# PY32F040xx register map
Vendor: Puya; Series: PY32F0; File version: 1.0.0
CPU: CM0+ r0p1, little endian, no MPU, no FPU, 4 interrupt priority bits
Registers are 32-bit, read-write, reset 0x0 unless marked. A register's access mark holds for its fields unless they carry their own. Offsets are from the block's base; [hi:lo] are bit positions; {n}, {i} and the like mark numbered series; 'fields as' and 'values as' point back to an identical list.

## ADC — Analog to Digital Converter
Base 0x40012400
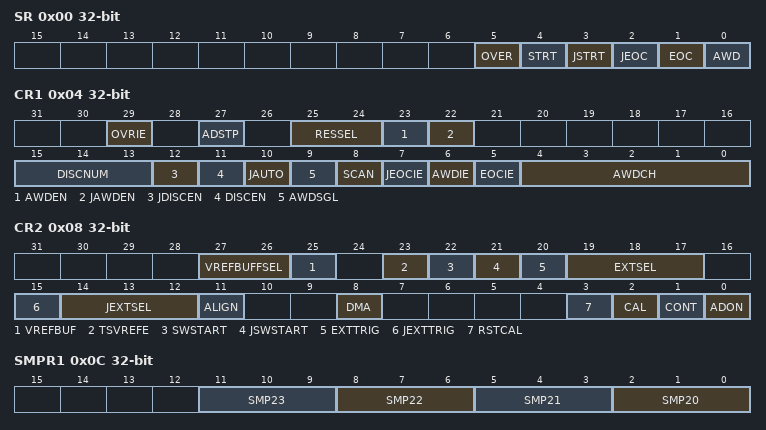
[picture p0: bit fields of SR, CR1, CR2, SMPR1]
0x00 SR
  [5] OVER
    on read: 0=No overload occurred; 1=Overload occurred | on write: 0=Clear the overload flag
  [4] STRT write-0-clears
    on read: 0=NotStarted (Rule channel conversion has not started); 1=Started (Rule channel conversion started) | on write: 0=Clear the Rule channel conversion start flag
  [3] JSTRT write-0-clears
    on read: 0=NotStarted (Injection channel conversion has not started); 1=Started (Injection channel conversion started) | on write: 0=Clear the Injection channel conversion start flag
  [2] JEOC write-0-clears
    on read: 0=NotComplete (Injection channel conversion is not complete); 1=Complete (Injection channel conversion complete) | on write: 0=Clear the Injection channel conversion flag
  [1] EOC write-0-clears
    on read: 0=NotComplete (Channel conversion is not complete); 1=Complete (Channel conversion complete) | on write: 0=Clear the channel conversion flag
  [0] AWD write-0-clears
    on read: 0=NoEvent (No analog watchdog event occurred); 1=Event (Analog watchdog event occurred) | on write: 0=Clear the analog watchdog event flag
0x04 CR1
  [29] OVRIE — desc OVETIE
    0=Disabled (Overload interrupt disabled); 1=Enabled (Overload interrupt enabled)
  [27] ADSTP
    on read: 0=NotStopping (No stop command active); 1=Stopping (ADC stopping conversion) | on write: 1=StopConversion (Stop the active conversion)
  [25:24] RESSEL
    0=TwelveBit (12 bits); 1=TenBit (10 bits); 2=EightBit (8 bits); 3=SixBit (6 bits)
  [23] AWDEN
    0=Disabled (Analog rule channel watchdog disabled); 1=Enabled (Analog rule channel watchdog enabled)
  [22] JAWDEN
    0=Disabled (Analog inject channel watchdog disabled); 1=Enabled (Analog inject channel watchdog enabled)
  [15:13] DISCNUM
  [12] JDISCEN
    0=Disabled (Analog inject channel intermittent mode disabled); 1=Enabled (Analog inject channel intermittent mode enabled)
  [11] DISCEN
    0=Disabled (Analog rule channel intermittent mode disabled); 1=Enabled (Analog rule channel intermittent mode enabled)
  [10] JAUTO
    0=Disabled (Analog auto inject disabled); 1=Enabled (Analog auto inject enabled)
  [9] AWDSGL
    0=Disabled (Analog watchdog on single channel disabled); 1=Enabled (Analog watchdog on single channel enabled)
  [8] SCAN
    0=Off (Scan mode off); 1=On (Scan mode on)
  [7] JEOCIE
    0=Disabled (Injection channel conversion end interrupt disabled); 1=Enabled (Injection channel conversion end interrupt enabled)
  [6] AWDIE
    0=Disabled (Analog watchdog interrupt disabled); 1=Enabled (Analog watchdog interrupt enabled)
  [5] EOCIE
    0=Disabled (Rule channel conversion end interrupt disabled); 1=Enabled (Rule channel conversion end interrupt enabled)
  [4:0] AWDCH range 0..15
0x08 CR2
  [27:26] VREFBUFFSEL — desc VERFBUFFERSEL
    0=OV1_5 (1.5V VREFBUF output voltage); 1=OV2_048 (2.048V VREFBUF output voltage); 2=OV2_5 (2.5V VREFBUF output voltage)
  [25] VREFBUF — desc VERFBUFFERE
    0=Disabled (Disable VREFBUF); 1=Enabled (Enable VREFBUF)
  [23] TSVREFE
    0=Disabled (Temperature sensor and VREFINT disabled); 1=Enabled (Temperature sensor and VREFINT enabled)
  [22] SWSTART
    on read: 0=Reset (Rule channel conversion reset); 1=Start (Rule channel conversion started) | on write: 1=StartConversion (Start rule channel conversion)
  [21] JSWSTART
    on read: 0=Reset (Injection channel conversion reset); 1=Start (Injection channel conversion started) | on write: 1=StartConversion (Start injection channel conversion)
  [20] EXTTRIG
    0=Disabled (External triggering of rule channel disabled); 1=Enabled (External triggering of rule channel enabled)
  [19:17] EXTSEL
    0=Timer1Ch1 (Timer1 Channel 1 event); 1=Timer1Ch2 (Timer1 Channel 2 event); 2=Timer1Ch3 (Timer1 Channel 3 event); 3=Timer2Ch2 (Timer2 Channel 2 event); 4=Timer3 TRGO event; 5=Timer15 TRGO event; 6=EXTI11 event; 7=SWSTART event
  [15] JEXTTRIG
    values as TSVREFE
  [14:12] JEXTSEL
    0=Timer1 TRGO event; 1=Timer1Ch4 (Timer1 Channel 4 event); 2=Timer2 TRGO event; 3=Timer2Ch1 (Timer2 Channel 1 event); 4=Timer3 TRGO event; 5=Timer15 TRGO event; 6=EXTI15 event; 7=JSWSTART event
  [11] ALIGN
    0=Right-aligned; 1=Left-aligned
  [8] DMA
    values as TSVREFE
  [3] RSTCAL
    on read: 0=IsInitialized (Calibration register is initialized); 1=Initialized (Calibration register initialized) | on write: 1=Reset (Calibration reset enable)
  [2] CAL
    on read: 0=Complete (Calibration complete); 1=Enabled calibration | on write: 1=StartCalibration
  [1] CONT
    0=Single conversion mode; 1=Continuous conversion mode
  [0] ADON
    values as TSVREFE
0x0C SMPR1
  [all] fields
    0=Cycles3_5 (3.5 cycles); 1=Cycles5_5 (5.5 cycles); 2=Cycles7_5 (7.5 cycles); 3=Cycles13_5 (13.5 cycles)
  [3n-58:3n-60] SMP{n} (n=20..23)
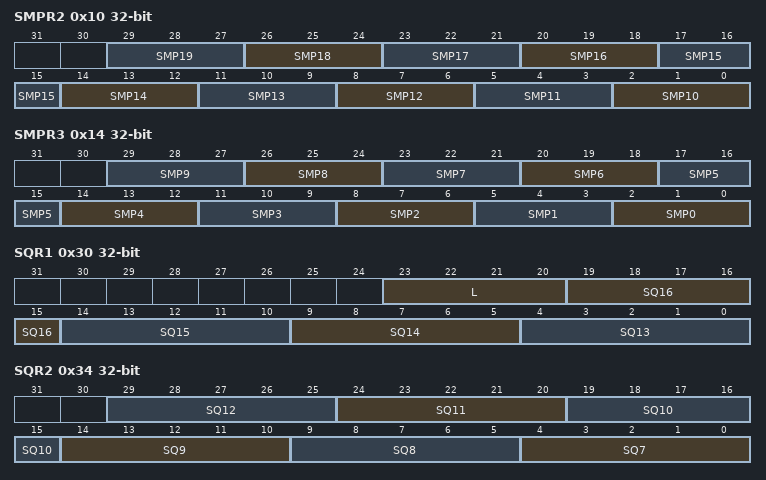
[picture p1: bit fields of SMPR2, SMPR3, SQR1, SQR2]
0x10 SMPR2
  [all] fields
    values as the fields of SMPR1
  [3n-28:3n-30] SMP{n} (n=10..19)
0x14 SMPR3 — desc SMPR2
  [all] fields
    values as the fields of SMPR1
  [3n+2:3n] SMP{n} (n=0..9)
{0x14+4i} JOFR{i} (i=1..4)
  [11:0] JOFFSET{i}
0x28 HTR
  [11:0] HT
0x2C LTR
  [11:0] LT
0x30 SQR1
  [23:20] L, [5n-61:5n-65] SQ{n} (n=13..16)
0x34 SQR2
  [5n-31:5n-35] SQ{n} (n=7..12)
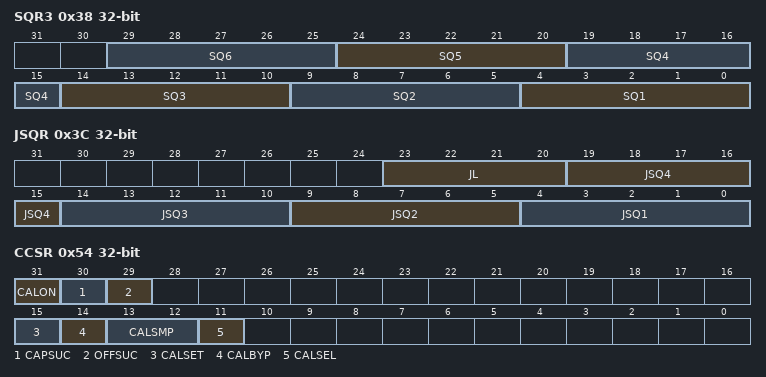
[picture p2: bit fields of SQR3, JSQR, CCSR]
0x38 SQR3
  [5n-1:5n-5] SQ{n} (n=1..6)
0x3C JSQR
  [23:20] JL
    0=Conversion1 (1 Conversion); 1=Transition2 (2 Transitions); 2=Conversion3 (3 Conversions); 3=Transition4 (4 Transitions)
  [5n-1:5n-5] JSQ{n} (n=1..4)
{0x3C+4i} JDR{i} ro (i=1..4)
  [15:0] JDR{i}
0x50 DR ro
  [15:0] DATA
0x54 CCSR
  [31] CALON ro
    0=InProgress (ADC calibration in progress); 1=Completed (ADC calibration completed or has not been initiated)
  [30] CAPSUC — desc CALFAIL
    on read: 0=NotSuccessful (Capacitance calibration not successful); 1=Successful (Capacitance calibration successful) | on write: 1=Clear (Set to zero)
  [29] OFFSUC
    on read: 0=NotSuccessful (Offset calibration not successful); 1=Successful (Offset calibration successful) | on write: 1=Clear (Set to zero)
  [15] CALSET
    on read: 0=Valid (Capacitance factor selection valid); 1=NotValid (Capacitance factor not valid) | on write: 1=Clear
  [14] CALBYP
    on read: 0=Valid (Calibration factor bypass not successful); 1=NotValid (Calibration factor bypass successful) | on write: 1=Clear
  [13:12] CALSMP
    0=Clock1 (1 ADC clock period); 1=Clock2 (2 ADC clock periods); 2=Clock4 (4 ADC clock periods); 3=Clock8 (8 ADC clock periods)
  [11] CALSEL
    0=OffsetLinearity (Calibration of OFFSET and linearity); 1=Offset (Calibration of OFFSET only)
